AUTOSAR XML (schema 00049)
package /ISOFT/PlatformComponents/ucm
  process design package_manager_design: executable=ucmd
package /ISOFT/PlatformComponents/ucm/exe
  executable ucmd: category=PLATFORM_LEVEL, build-type=BUILD-TYPE-DEBUG, logging-behavior=USES-LOGGING, minimum-timer-granularity=1000.0, reporting-behavior=REPORTS-EXECUTION-STATE, version=1.0.0
    root sw component prototype package_manager_root: application-type=ucm
package /ISOFT/PlatformComponents/ucm/swc
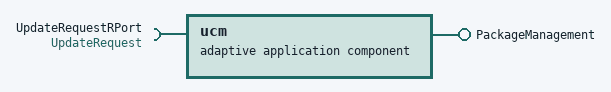
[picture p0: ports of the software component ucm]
  adaptive application sw component type ucm
    provide port PackageManagement: provided-interface=PackageManagement
    provide/require port SwPackageTransferStatusPRPort: provided-required-interface=SwPackageTransferStatus
    require port UpdateRequestRPort: required-interface=UpdateRequest
